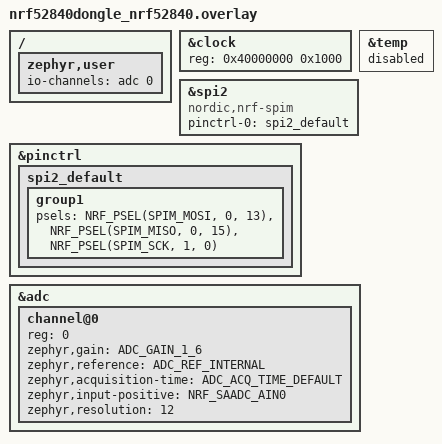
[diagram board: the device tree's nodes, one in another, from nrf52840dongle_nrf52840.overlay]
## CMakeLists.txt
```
cmake_minimum_required(VERSION 3.20.0)
find_package(Zephyr REQUIRED HINTS $ENV{ZEPHYR_BASE})

project(test)

target_sources(app PRIVATE src/main.c)
target_sources(app PRIVATE src/icm42688.c)
```

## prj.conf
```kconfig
CONFIG_SPI=y
CONFIG_GPIO=y
CONFIG_ADC=y
```

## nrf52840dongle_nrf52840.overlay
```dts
// To get started, press Ctrl+Space to bring up the completion menu and view the available nodes.

// You can also use the buttons in the sidebar to perform actions on nodes.
// Actions currently available include:

// * Enabling / disabling the node
// * Adding the bus to a bus
// * Removing the node
// * Connecting ADC channels

// For more help, browse the DeviceTree documentation at https://docs.zephyrproject.org/latest/guides/dts/index.html
// You can also visit the nRF DeviceTree extension documentation at https://nrfconnect.github.io/vscode-nrf-connect/devicetree/nrfdevicetree.html



&clock {
	reg = <0x40000000 0x1000>;
};
/delete-node/ &{/soc/spi@40004000/icm42688@0/};

&temp {
	status = "disabled";
};

&spi2 {
	status = "okay";
	pinctrl-0 = <&spi2_default>;
	pinctrl-names = "default";
	compatible = "nordic,nrf-spim";
};

&pinctrl {
	spi2_default: spi2_default {
		group1 {
			psels = <NRF_PSEL(SPIM_MOSI, 0, 13)>,
					<NRF_PSEL(SPIM_MISO, 0, 15)>,
					<NRF_PSEL(SPIM_SCK, 1, 0)>;
		};
	};
};

&adc {
	#address-cells = <1>;
	#size-cells = <0>;
	status = "okay";
	channel@0 {
		reg = <0>;
		zephyr,gain = "ADC_GAIN_1_6";
		zephyr,reference = "ADC_REF_INTERNAL";
		zephyr,acquisition-time = <ADC_ACQ_TIME_DEFAULT>;
		zephyr,input-positive = <NRF_SAADC_AIN0>;
		zephyr,resolution = <12>;
	};
};

/ {
	zephyr,user {
		io-channels = <&adc 0>;
	};
};
```

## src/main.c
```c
#include <zephyr/kernel.h>
#include <zephyr/drivers/gpio.h>



#define MY_GPIO0 DT_NODELABEL(gpio0)
#define LED_PIN 6

const struct device *gpio0_dev = DEVICE_DT_GET(MY_GPIO0);

int main(void)
{

  gpio_pin_configure(gpio0_dev, LED_PIN, GPIO_OUTPUT);
  
  max30102_init(&max30102, &hi2c1);
  max30102_reset(&max30102);
  max30102_clear_fifo(&max30102);
  max30102_set_fifo_config(&max30102, max30102_smp_ave_8, 1, 7);
  
  // Sensor settings
  max30102_set_led_pulse_width(&max30102, max30102_pw_16_bit);
  max30102_set_adc_resolution(&max30102, max30102_adc_2048);
  max30102_set_sampling_rate(&max30102, max30102_sr_800);
  max30102_set_led_current_1(&max30102, 6.2);
  max30102_set_led_current_2(&max30102, 6.2);

  // Enter SpO2 mode
  max30102_set_mode(&max30102, max30102_spo2);
  max30102_set_a_full(&max30102, 1);
  
  // Initiate 1 temperature measurement
  max30102_set_die_temp_en(&max30102, 1);
  max30102_set_die_temp_rdy(&max30102, 1);
  
  uint8_t en_reg[2] = {0};
  max30102_read(&max30102, 0x00, en_reg, 1);
  
  

  while (1)
  {
    gpio_pin_toggle(gpio0_dev, LED_PIN);

	if (max30102_has_interrupt(&max30102))
    {
      max30102_interrupt_handler(&max30102);
    }
	
    k_msleep(1000);
  }
}
```

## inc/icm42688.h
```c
#pragma once

#include <stdint.h>
#include "icm42688_registers.h"
#include "icm42688_config.h"
#include <zephyr/drivers/spi.h>




typedef struct icm42688_struct icm42688_struct;

// Interfaces
typedef void      (*icm42688_interface_init)					(icm42688_struct*);
typedef int       (*icm42688_interface_begin)			    	(icm42688_struct*);	
typedef int       (*icm42688_interface_spi_init)		        (icm42688_struct*);
typedef int       (*icm42688_interface_spi_begin)		        (icm42688_struct*);	
typedef float     (*icm42688_interface_getTemperature)	    	(icm42688_struct*);
typedef float     (*icm42688_interface_getAccelDataX)	    	(icm42688_struct*);	
typedef float     (*icm42688_interface_getAccelDataY)	    	(icm42688_struct*);	
typedef float     (*icm42688_interface_getAccelDataZ)		    (icm42688_struct*);	
typedef float     (*icm42688_interface_getGyrolDataX)		    (icm42688_struct*);	
typedef float     (*icm42688_interface_getGyroDataY)		    (icm42688_struct*);	
typedef float     (*icm42688_interface_getGyroDataZ)		    (icm42688_struct*);	
typedef void      (*icm42688_interface_tapDetectionInit)		(icm42688_struct*,uint8_t);
typedef void      (*icm42688_interface_getTapInformation)		(icm42688_struct*);
typedef uint8_t   (*icm42688_interface_numberOfTap)	            (icm42688_struct*);
typedef uint8_t   (*icm42688_interface_axisOfTap)	            (icm42688_struct*);
typedef void      (*icm42688_interface_wakeOnMotionInit)		(icm42688_struct*);
typedef void      (*icm42688_interface_setWOMTh)		        (icm42688_struct*,uint8_t,uint8_t);
typedef void      (*icm42688_interface_setWOMInterrupt)		(icm42688_struct*,uint8_t);
typedef void      (*icm42688_interface_enableSMDInterrupt)		(icm42688_struct*,uint8_t);
typedef uint8_t   (*icm42688_interface_readInterruptStatus)	    (icm42688_struct*,uint8_t);
typedef bool      (*icm42688_interface_setODRAndFSR)	        (icm42688_struct*,uint8_t,uint8_t,uint8_t);
typedef void      (*icm42688_interface_startFIFOMode)	        (icm42688_struct*);
typedef void      (*icm42688_interface_stopFIFOMode)	        (icm42688_struct*);
typedef void      (*icm42688_interface_getFIFOData)	            (icm42688_struct*);
typedef void      (*icm42688_interface_setINTMode)	            (icm42688_struct*,uint8_t,uint8_t,uint8_t,uint8_t);
typedef void      (*icm42688_interface_startGyroMeasure)		(icm42688_struct*,uint8_t);
typedef void      (*icm42688_interface_startAccelMeasure)		(icm42688_struct*,uint8_t);
typedef void      (*icm42688_interface_startTempMeasure)	    (icm42688_struct*);

/// @brief Protected
typedef void      (*icm42688_interface_writeReg)				(uint8_t,void*,size_t);
typedef uint8_t    (*icm42688_interface_readReg)				(icm42688_struct*,uint8_t, void*,uint8_t);
typedef void      (*icm42688_interface_setFIFODataMode)	(icm42688_struct*);

/// @brief Private 
typedef void      (*icm42688_interface_setGyroNotchFilterFHz)	(icm42688_struct*,double,uint8_t);
typedef void      (*icm42688_interface_setGyroNFbandwidth)		(icm42688_struct*,uint8_t);
typedef void      (*icm42688_interface_setGyroNotchFilter)		(icm42688_struct*,bool);
typedef void      (*icm42688_interface_setAAFBandwidth)		    (icm42688_struct*,uint8_t,uint8_t);
typedef void      (*icm42688_interface_setAAF)		            (icm42688_struct*,uint8_t,bool);
typedef void      (*icm42688_interface_setUIFilter)		        (icm42688_struct*,uint8_t,uint8_t,uint8_t);

struct icm42688_struct{

  uint8_t _r;
  uint8_t _g;
  uint8_t _b;
  uint8_t _mode;
  uint8_t _tapNum ;
  uint8_t _tapAxis;
  uint8_t _tapDir ;
  float _gyroRange;
  float _accelRange;
  bool FIFOMode;
  int16_t _accelX;
  int16_t _accelY;
  int16_t _accelZ;
  int16_t _gyroX;
  int16_t _gyroZ;
  int16_t _gyroY;
  int8_t _temp;
  int8_t _INTPin;

  sAccelConfig0_t accelConfig0;
  sPWRMgmt0_t PWRMgmt0;
  sINTFConfig1_t INTFConfig1;
  sAccelConfig1_t accelConfig1;
  sGyroAccelConfig0_t gyroAccelConfig0;
  sAPEXConfig7_t APEXConfig7;
  sAPEXConfig8_t APEXConfig8;
  sSMDConfig_t SMDConfig;
  sGyroConfig1_t  gyroConfig1;
  sFIFOConfig1_t FIFOConfig1;
  sINTConfig_t INTConfig;
  sGyroConfig0_t gyroConfig0;
  sAPEXConfig0_t APEXConfig0;
  sGyroConfigStatic9_t gyroConfigStatic9;
  sGyroConfigStatic2_t gyroConfigStatic2;
  sGyroConfigStatic5_t gyroConfigStatic5;
  sAccelConfigStatic2_t accelConfigStatic2;
  sAccelConfigStatic4_t accelConfigStatic4;
  sINTSource_t  INTSource;

  icm42688_interface_begin	                begin;  
  icm42688_interface_spi_init		            spi_init;  
  icm42688_interface_spi_begin		          spi_begin;  
  icm42688_interface_getTemperature	        getTemperature;  
  icm42688_interface_getAccelDataX	        getAccelDataX;  
  icm42688_interface_getAccelDataY	        getAccelDataY;  
  icm42688_interface_getAccelDataZ		      getAccelDataZ;  
  icm42688_interface_getGyrolDataX		      getGyroDataX;  
  icm42688_interface_getGyroDataY		        getGyroDataY;  
  icm42688_interface_getGyroDataZ		        getGyroDataZ;  
  icm42688_interface_tapDetectionInit	      tapDetectionInit;  
  icm42688_interface_getTapInformation	    getTapInformation;  
  icm42688_interface_numberOfTap	          numberOfTap;  
  icm42688_interface_axisOfTap	            axisOfTap;  
  icm42688_interface_wakeOnMotionInit	      wakeOnMotionInit;  
  icm42688_interface_setWOMTh		            setWOMTh;  
  icm42688_interface_setWOMInterrupt        setWOMInterrupt;  
  icm42688_interface_enableSMDInterrupt	    enableSMDInterrupt;  
  icm42688_interface_readInterruptStatus	  readInterruptStatus;  
  icm42688_interface_setODRAndFSR	          setODRAndFSR;  
  icm42688_interface_startFIFOMode	        startFIFOMode;	    
  icm42688_interface_stopFIFOMode	          stopFIFOMode;	   
  icm42688_interface_getFIFOData	          getFIFOData;	         
  icm42688_interface_setINTMode	            setINTMode;	         
  icm42688_interface_startGyroMeasure	      startGyroMeasure;  
  icm42688_interface_startAccelMeasure	    startAccelMeasure;  
  icm42688_interface_startTempMeasure	      startTempMeasure;  
                                                                    
                                                                    
  icm42688_interface_writeReg			          writeReg;			 
  icm42688_interface_readReg				        readReg;		
  icm42688_interface_setFIFODataMode	      setFIFODataMode;	    
                                                                    
                                                                    
  icm42688_interface_setGyroNotchFilterFHz  setGyroNotchFilterFHz; 
  icm42688_interface_setGyroNFbandwidth	    setGyroNFbandwidth;	 
  icm42688_interface_setGyroNotchFilter	    setGyroNotchFilter;	 
  icm42688_interface_setAAFBandwidth		    setAAFBandwidth;		 
  icm42688_interface_setAAF		              setAAF;		         
  icm42688_interface_setUIFilter	          setUIFilter;	         	    


};

void icm42688();
  /**
   * @fn begin
   * @brief Init function
   * @return Init result
   * @retval ERR_OK         Init succeed
   * @retval ERR_DATA_BUS   Bus data read error
   * @retval ERR_IC_VERSION The read Sensor ID is wrong
   */
int icm42688_begin(icm42688_struct *s);

int icm42688_spi_init(icm42688_struct*);

int icm42688_spi_begin(icm42688_struct *s);


void icm42688_writeReg(uint8_t reg, void* pBuf, size_t size) ;

uint8_t icm42688_readReg(icm42688_struct *s,uint8_t reg, void* pBuf, uint8_t size);



float icm42688_getTemperature(icm42688_struct *s);

  /**
   * @fn getAccelDataX
   * @brief Get X-axis accelerometer value
   * @return X-axis accelerometer value, unit: mg
   */
float icm42688_getAccelDataX(icm42688_struct *s);

  /**
   * @fn getAccelDataY
   * @brief Get Y-axis accelerometer value
   * @return Y-axis accelerometer value, unit: mg
   */
float icm42688_getAccelDataY(icm42688_struct *s);

  /**
   * @fn getAccelDataZ
   * @brief Get Z-axis accelerometer value
   * @return Z-axis accelerometer value, unit: mg
   */
float icm42688_getAccelDataZ(icm42688_struct *s);

  /**
   * @fn getGyroDataX
   * @brief Get X-axis gyroscope value
   * @return X-axis gyroscope value, unit: dps
   */
float icm42688_getGyroDataX(icm42688_struct *s);

  /**
   * @fn getGyroDataY
   * @brief Get Y-axis gyroscope value
   * @return Y-axis gyroscope value, unit: dps
   */
float icm42688_getGyroDataY(icm42688_struct *s);

  /**
   * @fn getGyroDataZ
   * @brief Get Z-axis gyroscope value
   * @return Z-axis gyroscope value, unit: dps
   */
float icm42688_getGyroDataZ(icm42688_struct *s);

  /**
   * @fn tapDetectionInit
   * @brief Tap detection init
   * @param accelMode Accelerometer operating mode
   * @n      0 for operating in low-power mode
   * @n      1 for operating in low-noise mode
   */
void icm42688_tapDetectionInit(icm42688_struct *s,uint8_t accelMode);

  /**
   * @fn getTapInformation
   * @brief Get tap information
   */
void icm42688_getTapInformation(icm42688_struct *s);

  /**
   * @fn numberOfTap
   * @brief Get the number of tap: single-tap or double tap
   * @return The number of tap
   * @retval TAP_SINGLE   Single-tap
   * @retval TAP_DOUBLE   Double tap
   */
uint8_t icm42688_numberOfTap(icm42688_struct *s);

  /**
   * @fn axisOfTap
   * @brief Get the axis on which the tap occurred: X-axis, Y-axis, or Z-axis
   * @return Tap axis
   * @retval X_AXIS   X-axis
   * @retval Y_AXIS   Y-axis
   * @retval Z_AXIS   Z-axis
   */
uint8_t icm42688_axisOfTap(icm42688_struct *s);

  /**
   * @fn wakeOnMotionInit
   * @brief Wake on motion init
   */
void icm42688_wakeOnMotionInit(icm42688_struct *s);

  /**
   * @fn setWOMTh
   * @brief Set wake on motion interrupt threshold of axis accelerometer
   * @param axis  x/y/z轴
   * @n       X_AXIS_WOM
   * @n       Y_AXIS_WOM
   * @n       Z_AXIS_WOM
   * @n       ALL
   * @param threshold  Range(0-255) [WoM thresholds are expressed in fixed “mg” independent of the selected Range [0g : 1g]; Resolution 1g/256=~3.9mg]
   */
void icm42688_setWOMTh(icm42688_struct *s,uint8_t axis,uint8_t threshold);

  /**
   * @fn setWOMInterrupt
   * @brief Enable wake on motion interrupt
   * @param axis  X-axis, Y-axis, or Z-axis
   * @n       X_AXIS_WOM
   * @n       Y_AXIS_WOM
   * @n       Z_AXIS_WOM
   */
void icm42688_setWOMInterrupt(icm42688_struct *s,uint8_t axis);

  /**
   * @fn enableSMDInterrupt
   * @brief Set important motion detection mode and enable SMD interrupt
   * @param mode  
   * @n      0: disable SMD
   * @n      2 : SMD short (1 sec wait) An SMD event is detected when two WOM are detected 1 sec apart
   * @n      3 : SMD long (3 sec wait) An SMD event is detected when two WOM are detected 3 sec apart
   */
void icm42688_enableSMDInterrupt(icm42688_struct *s,uint8_t mode);

  /**
   * @fn readInterruptStatus
   * @brief Read interrupt information and clear interrupt
   * @param reg Interrupt information register
   * @n      ICM42688_INT_STATUS2    Obtain interrupt information of SMD_INT, WOM_X_INT, WOM_Y_INT, WOM_Z_INT and clear them
   * @n      ICM42688_INT_STATUS3    Obtain interrupt information of STEP_DET_INT, STEP_CNT_OVF_INT, TILT_DET_INT, WAKE_INT, TAP_DET_INT and clear them
   * @return Interrupt information, return 0 when no interrupt.
   */
uint8_t icm42688_readInterruptStatus(icm42688_struct *s,uint8_t reg);

  /**
   * @fn setODRAndFSR
   * @brief Set ODR and Full-scale range of gyroscope or accelerometer.
   * @param who  GYRO/ACCEL/ALL
   * @n       GYRO: indicate only set gyroscope
   * @n       ACCEL: indicate only set accelerometer
   * @param ODR Output data rate
   * @n       ODR_32KHZ         Support: Gyro/Accel(LN mode)
   * @n       ODR_16KHZ         Support: Gyro/Accel(LN mode)
   * @n       ODR_8KHZ          Support: Gyro/Accel(LN mode)
   * @n       ODR_4KHZ          Support: Gyro/Accel(LN mode)
   * @n       ODR_2KHZ          Support: Gyro/Accel(LN mode)
   * @n       ODR_1KHZ          Support: Gyro/Accel(LN mode)
   * @n       ODR_200HZ         Support: Gyro/Accel(LP or LN mode)
   * @n       ODR_100HZ         Support: Gyro/Accel(LP or LN mode)
   * @n       ODR_50HZ          Support: Gyro/Accel(LP or LN mode)
   * @n       ODR_25KHZ         Support: Gyro/Accel(LP or LN mode)
   * @n       ODR_12_5KHZ       Support: Gyro/Accel(LP or LN mode)
   * @n       ODR_6_25KHZ       Support: Accel(LP mode)
   * @n       ODR_3_125HZ       Support: Accel(LP mode)
   * @n       ODR_1_5625HZ      Support: Accel(LP mode)
   * @n       ODR_500HZ         Support: Accel(LP or LN mode)
   * @param FSR Full-scale range
   * @n       FSR_0      Gyro:±2000dps   /   Accel: ±16g
   * @n       FSR_1      Gyro:±1000dps   /   Accel: ±8g
   * @n       FSR_2      Gyro:±500dps    /   Accel: ±4g
   * @n       FSR_3      Gyro:±250dps    /   Accel: ±2g
   * @n       FSR_4      Gyro:±125dps    /   Accel: not optional
   * @n       FSR_5      Gyro:±62.5dps   /   Accel: not optional
   * @n       FSR_6      Gyro:±31.25dps  /   Accel: not optional
   * @n       FSR_7      Gyro:±15.625dps /   Accel: not optional
   * @return Set result
   * @retval true   indicate the setting succeeds
   * @retval flase  indicate selected parameter is wrong
   */
bool icm42688_setODRAndFSR(icm42688_struct *s,uint8_t who,uint8_t ODR,uint8_t FSR);

  /**
   * @fn startFIFOMode
   * @brief Enable FIFO
   */
void icm42688_startFIFOMode(icm42688_struct *s);

  /**
   * @fn sotpFIFOMode
   * @brief Disable FIFO
   */
void icm42688_stopFIFOMode(icm42688_struct *s);

  /**
   * @fn getFIFOData
   * @brief Read FIFO data, read temperature, gyroscope and accelerometer data and save them for parse.
   */
void icm42688_getFIFOData(icm42688_struct *s);

  /**
   * @fn setINTMode
   * @brief Set interrupt mode
   * @param INTPin  Interrupt pin 
   * @n       1  Use INT1 interrupt pin
   * @n       2  Use INT2 interrupt pin
   * @param INTmode Set interrupt mode
   * @n       1  Interrupt lock mode (polarity remains unchanged when interrupt triggered, and restore after clearing interrupt)
   * @n       0  Pulse mode
   * @param INTPolarity Level polarity output by interrupt
   * @n       0  Interrupt pin polarity is LOW when producing interrupt
   * @n       1  Interrupt pin polarity is HIGH when producing interrupt
   * @param INTDriveCircuit  
   * @n       0  Open drain
   * @n       1  Push pull
   */
void icm42688_setINTMode(icm42688_struct *s,uint8_t INTPin,uint8_t INTmode,uint8_t INTPolarity,uint8_t INTDriveCircuit);

  /**
   * @fn startGyroMeasure
   * @brief Start gyroscope
   * @param mode Set gyroscope working mode
   * @n       STANDBY_MODE_ONLY_GYRO 1  Set stanby mode, only support gyroscope
   * @n       LN_MODE  3                Set low-noise mode
   */
void icm42688_startGyroMeasure(icm42688_struct *s,uint8_t mode);

  /**
   * @fn startAccelMeasure
   * @brief Start accelerometer
   * @param mode Set accelerometer working mode
   * @n       LP_MODE_ONLY_ACCEL  2     Set low-power mode, only support accelerometer
   * @n       LN_MODE  3                Set low-noise mode
   */
void icm42688_startAccelMeasure(icm42688_struct *s,uint8_t mode);

  /**
   * @fn startTempMeasure
   * @brief Start thermometer
   */
void icm42688_startTempMeasure(icm42688_struct *s);


  /**
   * @fn setFIFODataMode
   * @brief Set FIFO data packet format
   */
void icm42688_setFIFODataMode(icm42688_struct *s);
```

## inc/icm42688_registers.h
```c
#define DFRobot_ICM42688_I2C_L_ADDR 0x68 
#define DFRobot_ICM42688_I2C_H_ADDR 0x69
#define DFRobot_ICM42688_ID  0x47 

#define ICM42688_DEVICE_CONFIG          0x11
#define ICM42688_DRIVE_CONFIG           0x13

#define ICM42688_SIGNAL_PATH_RESET      0x4B

#define ICM42688_PWR_MGMT0              0x4E

#define ICM42688_INT_CONFIG             0x14
#define ICM42688_INT_STATUS             0x2D
#define ICM42688_INT_STATUS2            0x37
#define ICM42688_INT_STATUS3            0x38
#define ICM42688_INT_CONFIG0            0x63
#define ICM42688_INT_CONFIG1            0x64
#define ICM42688_INT_SOURCE0            0x65
#define ICM42688_INT_SOURCE1            0x66
#define ICM42688_INT_SOURCE3            0x68
#define ICM42688_INT_SOURCE4            0x69
#define ICM42688_INT_SOURCE6            0x4D
#define ICM42688_INT_SOURCE7            0x4E
#define ICM42688_INT_SOURCE8            0x4F
#define ICM42688_INT_SOURCE9            0x50
#define ICM42688_INT_SOURCE10           0x51

#define ICM42688_TEMP_DATA1             0x1D
#define ICM42688_TEMP_DATA0             0x1E
#define ICM42688_ACCEL_DATA_X1          0x1F
#define ICM42688_ACCEL_DATA_X0          0x20
#define ICM42688_ACCEL_DATA_Y1          0x21
#define ICM42688_ACCEL_DATA_Y0          0x22
#define ICM42688_ACCEL_DATA_Z1          0x23
#define ICM42688_ACCEL_DATA_Z0          0x24
#define ICM42688_GYRO_DATA_X1           0x25
#define ICM42688_GYRO_DATA_X0           0x26
#define ICM42688_GYRO_DATA_Y1           0x27
#define ICM42688_GYRO_DATA_Y0           0x28
#define ICM42688_GYRO_DATA_Z1           0x29
#define ICM42688_GYRO_DATA_Z0           0x30

#define ICM42688_TMST_FSYNCH            0x43
#define ICM42688_TMST_FSYNCL            0x44

#define ICM42688_GYRO_CONFIG_STATIC2    0x0B
#define ICM42688_GYRO_CONFIG_STATIC3    0x0C
#define ICM42688_GYRO_CONFIG_STATIC4    0x0D
#define ICM42688_GYRO_CONFIG_STATIC5    0x0E
#define ICM42688_GYRO_CONFIG_STATIC6    0x0F
#define ICM42688_GYRO_CONFIG_STATIC7    0x10
#define ICM42688_GYRO_CONFIG_STATIC8    0x11
#define ICM42688_GYRO_CONFIG_STATIC9    0x12
#define ICM42688_GYRO_CONFIG_STATIC10   0x13


    
#define ICM42688_GYRO_CONFIG0           0x4F
#define ICM42688_ACCEL_CONFIG0          0x50
#define ICM42688_GYRO_CONFIG1           0x51
#define ICM42688_GYRO_ACCEL_CONFIG0     0x52
#define ICM42688_ACCEL_CONFIG1          0x53
    
#define ICM42688_TMST_CONFIG            0x54
    

#define ICM42688_SMD_CONFIG             0x57

#define ICM42688_FIFO_CONFIG            0x16
#define ICM42688_FIFO_COUNTH            0x2E
#define ICM42688_FIFO_COUNTL            0x2F
#define ICM42688_FIFO_DATA              0x30
#define ICM42688_FIFO_CONFIG1           0x5F
#define ICM42688_FIFO_CONFIG2           0x60
#define ICM42688_FIFO_CONFIG3           0x61
#define ICM42688_FIFO_LOST_PKT0         0x6C
#define ICM42688_FIFO_LOST_PKT1         0x6D

#define ICM42688_FSYNC_CONFIG           0x62
    

    

#define ICM42688_SELF_TEST_CONFIG       0x70
#define ICM42688_WHO_AM_I               0x75
#define ICM42688_REG_BANK_SEL           0x76   
#define ICM42688_SENSOR_CONFIG0         0x03



#define ICM42688_XG_ST_DATA             0x5F
#define ICM42688_YG_ST_DATA             0x60
#define ICM42688_ZG_ST_DATA             0x61

#define ICM42688_TMSTVAL0               0x62
#define ICM42688_TMSTVAL1               0x63
#define ICM42688_TMSTVAL2               0x64

#define ICM42688_INTF_CONFIG0           0x4C
#define ICM42688_INTF_CONFIG1           0x4D
#define ICM42688_INTF_CONFIG4           0x7A
#define ICM42688_INTF_CONFIG5           0x7B
#define ICM42688_INTF_CONFIG6           0x7C

#define ICM42688_ACCEL_CONFIG_STATIC2   0x03
#define ICM42688_ACCEL_CONFIG_STATIC3   0x04
#define ICM42688_ACCEL_CONFIG_STATIC4   0x05

#define ICM42688_XA_ST_DATA             0x3B
#define ICM42688_YA_ST_DATA             0x3C
#define ICM42688_ZA_ST_DATA             0x3D

#define ICM42688_APEX_DATA0             0x31
#define ICM42688_APEX_DATA1             0x32
#define ICM42688_APEX_DATA2             0x33
#define ICM42688_APEX_DATA3             0x34
#define ICM42688_APEX_DATA4             0x35
#define ICM42688_APEX_DATA5             0x36
#define ICM42688_APEX_CONFIG0           0x56
#define ICM42688_APEX_CONFIG1           0x40 
#define ICM42688_APEX_CONFIG2           0x41
#define ICM42688_APEX_CONFIG3           0x42
#define ICM42688_APEX_CONFIG4           0x43
#define ICM42688_APEX_CONFIG5           0x44
#define ICM42688_APEX_CONFIG6           0x45
#define ICM42688_APEX_CONFIG7           0x46
#define ICM42688_APEX_CONFIG8           0x47
#define ICM42688_APEX_CONFIG9           0x48

#define ICM42688_ACCEL_WOM_X_THR        0x4A
#define ICM42688_ACCEL_WOM_Y_THR        0x4B
#define ICM42688_ACCEL_WOM_Z_THR        0x4C

#define ICM42688_OFFSET_USER0           0x77
#define ICM42688_OFFSET_USER1           0x78
#define ICM42688_OFFSET_USER2           0x79
#define ICM42688_OFFSET_USER3           0x7A
#define ICM42688_OFFSET_USER4           0x7B
#define ICM42688_OFFSET_USER5           0x7C
#define ICM42688_OFFSET_USER6           0x7D
#define ICM42688_OFFSET_USER7           0x7E
#define ICM42688_OFFSET_USER8           0x7F

#define ICM42688_STEP_DET_INT           1<<5
#define ICM42688_STEP_CNT_OVF_INT       1<<4
#define ICM42688_TILT_DET_INT           1<<3
#define ICM42688_WAKE_INT               1<<2
#define ICM42688_SLEEP_INT              1<<1
#define ICM42688_TAP_DET_INT            1

#define ICM42688_SMD_INT                1<<3
#define ICM42688_WOM_Z_INT              1<<2
#define ICM42688_WOM_Y_INT              1<<1
#define ICM42688_WOM_X_INT              1

#define ICM42688_STATUS_WALK 1
#define ICM42688_STATUS_RUN 2

//////////////////////////////////////////////////////////////////////////////////////////////////////


  #define ERR_OK             0      ///< No error
  #define ERR_DATA_BUS      -1      ///< Data bus error
  #define ERR_IC_VERSION    -2      ///< The chip version not match
  
  #define GYRO     0
  #define ACCEL    1
  #define ALL      5



  #define TMST_DEFAULT_CONFIG_START  0x23
  #define TMST_VALUE_DIS             0<<4
  #define TMST_VALUE_EN              1<<4
  #define TMST_RES_EN_DIS            0<<3 
  #define TMST_RES_EN                1<<3
  #define TMST_FSYNC_EN              1<<1
  #define TMST_FSYNC_DIS             0<<1
  #define TMST_DELTA_EN              0<<2
  #define TMST_DELTA_DIS             1<<2
  #define TMST_EN                    1
  #define TMST_DIS                   0

  #define X_AXIS   0
  #define Y_AXIS   2
  #define Z_AXIS   4

  #define X_AXIS_WOM   1
  #define Y_AXIS_WOM   2
  #define Z_AXIS_WOM   4

  #define ODR_32KHZ         1
  #define ODR_16KHZ         2
  #define ODR_8KHZ          3
  #define ODR_4KHZ          4
  #define ODR_2KHZ          5
  #define ODR_1KHZ          6
  #define ODR_200HZ         7
  #define ODR_100HZ         8
  #define ODR_50HZ          9
  #define ODR_25KHZ         10
  #define ODR_12_5KHZ       11
  #define ODR_6_25KHZ       12
  #define ODR_3_125HZ       13
  #define ODR_1_5625HZ      14
  #define ODR_500HZ         15

  #define FSR_0             0
  #define FSR_1             1
  #define FSR_2             2
  #define FSR_3             3
  #define FSR_4             4
  #define FSR_5             5
  #define FSR_6             6
  #define FSR_7             7

  #define LP_MODE_ONLY_ACCEL  2
  #define LN_MODE  3
  #define STANDBY_MODE_ONLY_GYRO 1 
  #define OFF_MODE   0

  #define TAP_SINGLE 8
  #define TAP_DOUBLE 16
```

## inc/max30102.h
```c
#pragma once


#include "max30102_defines.h"


#include "main.h"
#include <stdint.h>
#include <string.h>
#include <stdlib.h>
#include <string.h>


typedef enum max30102_mode_t
{
    max30102_heart_rate = 0x02,
    max30102_spo2 = 0x03,
    max30102_multi_led = 0x07
} max30102_mode_t;

typedef enum max30102_smp_ave_t
{
    max30102_smp_ave_1,
    max30102_smp_ave_2,
    max30102_smp_ave_4,
    max30102_smp_ave_8,
    max30102_smp_ave_16,
    max30102_smp_ave_32,
} max30102_smp_ave_t;

typedef enum max30102_sr_t
{
    max30102_sr_50,
    max30102_sr_100,
    max30102_sr_200,
    max30102_sr_400,
    max30102_sr_800,
    max30102_sr_1000,
    max30102_sr_1600,
    max30102_sr_3200
} max30102_sr_t;

typedef enum max30102_led_pw_t
{
    max30102_pw_15_bit,
    max30102_pw_16_bit,
    max30102_pw_17_bit,
    max30102_pw_18_bit
} max30102_led_pw_t;

typedef enum max30102_adc_t
{
    max30102_adc_2048,
    max30102_adc_4096,
    max30102_adc_8192,
    max30102_adc_16384
} max30102_adc_t;

typedef enum max30102_multi_led_ctrl_t
{
    max30102_led_off,
    max30102_led_red,
    max30102_led_ir
} max30102_multi_led_ctrl_t;

typedef struct max30102_t
{
    I2C_HandleTypeDef *_ui2c;
    uint32_t _ir_samples[32];
    uint32_t _red_samples[32];
    uint8_t _interrupt_flag;
} max30102_t;

void max30102_plot(uint32_t ir_sample, uint32_t red_sample);

void max30102_init(max30102_t *obj, I2C_HandleTypeDef *hi2c);
void max30102_write(max30102_t *obj, uint8_t reg, uint8_t *buf, uint16_t buflen);
void max30102_read(max30102_t *obj, uint8_t reg, uint8_t *buf, uint16_t buflen);

void max30102_reset(max30102_t *obj);

void max30102_set_a_full(max30102_t *obj, uint8_t enable);
void max30102_set_ppg_rdy(max30102_t *obj, uint8_t enable);
void max30102_set_alc_ovf(max30102_t *obj, uint8_t enable);
void max30102_set_die_temp_rdy(max30102_t *obj, uint8_t enable);
void max30102_set_die_temp_en(max30102_t *obj, uint8_t enable);

void max30102_on_interrupt(max30102_t *obj);
uint8_t max30102_has_interrupt(max30102_t *obj);
void max30102_interrupt_handler(max30102_t *obj);

void max30102_shutdown(max30102_t *obj, uint8_t shdn);

void max30102_set_mode(max30102_t *obj, max30102_mode_t mode);
void max30102_set_sampling_rate(max30102_t *obj, max30102_sr_t sr);

void max30102_set_led_pulse_width(max30102_t *obj, max30102_led_pw_t pw);
void max30102_set_adc_resolution(max30102_t *obj, max30102_adc_t adc);

void max30102_set_led_current_1(max30102_t *obj, float ma);
void max30102_set_led_current_2(max30102_t *obj, float ma);
void max30102_set_multi_led_slot_1_2(max30102_t *obj, max30102_multi_led_ctrl_t slot1, max30102_multi_led_ctrl_t slot2);
void max30102_set_multi_led_slot_3_4(max30102_t *obj, max30102_multi_led_ctrl_t slot3, max30102_multi_led_ctrl_t slot4);

void max30102_set_fifo_config(max30102_t *obj, max30102_smp_ave_t smp_ave, uint8_t roll_over_en, uint8_t fifo_a_full);
void max30102_clear_fifo(max30102_t *obj);
void max30102_read_fifo(max30102_t *obj);

void max30102_read_temp(max30102_t *obj, int8_t *temp_int, uint8_t *temp_frac);

#endif
```

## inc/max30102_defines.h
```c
#pragma once

#define MAX30102_I2C_ADDR 0x57
#define MAX30102_I2C_TIMEOUT 1000

#define MAX30102_BYTES_PER_SAMPLE 6
#define MAX30102_SAMPLE_LEN_MAX 32

#define MAX30102_INTERRUPT_STATUS_1 0x00
#define MAX30102_INTERRUPT_STATUS_2 0x01
#define MAX30102_INTERRUPT_ENABLE_1 0x02
#define MAX30102_INTERRUPT_ENABLE_2 0x03
#define MAX30102_INTERRUPT_A_FULL 7
#define MAX30102_INTERRUPT_PPG_RDY 6
#define MAX30102_INTERRUPT_ALC_OVF 5
#define MAX30102_INTERRUPT_DIE_TEMP_RDY 1

#define MAX30102_FIFO_WR_PTR 0x04
#define MAX30102_OVF_COUNTER 0x05
#define MAX30102_FIFO_RD_PTR 0x06

#define MAX30102_FIFO_DATA 0x07

#define MAX30102_FIFO_CONFIG 0x08
#define MAX30102_FIFO_CONFIG_SMP_AVE 5
#define MAX30102_FIFO_CONFIG_ROLL_OVER_EN 4
#define MAX30102_FIFO_CONFIG_FIFO_A_FULL 0

#define MAX30102_MODE_CONFIG 0x09
#define MAX30102_MODE_SHDN 7
#define MAX30102_MODE_RESET 6
#define MAX30102_MODE_MODE 0

#define MAX30102_SPO2_CONFIG 0x0a
#define MAX30102_SPO2_ADC_RGE 5
#define MAX30102_SPO2_SR 2
#define MAX30102_SPO2_LEW_PW 0

#define MAX30102_LED_IR_PA1 0x0c
#define MAX30102_LED_RED_PA2 0x0d

#define MAX30102_MULTI_LED_CTRL_1 0x11
#define MAX30102_MULTI_LED_CTRL_SLOT2 4
#define MAX30102_MULTI_LED_CTRL_SLOT1 0
#define MAX30102_MULTI_LED_CTRL_2 0x12
#define MAX30102_MULTI_LED_CTRL_SLOT4 4
#define MAX30102_MULTI_LED_CTRL_SLOT3 0

#define MAX30102_DIE_TINT 0x1f
#define MAX30102_DIE_TFRAC 0x20
#define MAX30102_DIE_TFRAC_INCREMENT 0.0625f
#define MAX30102_DIE_TEMP_CONFIG 0x21
#define MAX30102_DIE_TEMP_EN 1


// FOR TEST 
#define DEBUG_PRINT
```

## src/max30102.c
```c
#include "max30102.h"

#include <zephyr.h>
#include <device.h>
#include <drivers/i2c.h>
#include <stdio.h>

#ifdef __cplusplus
extern "C"
{
#endif

/**
 * @brief Built-in plotting function. Called during an interrupt to print/plot the current sample.
 * @note Override this in your main.c if you do not use printf() for printing.
 * @param ir_sample
 * @param red_sample
 */
__weak void max30102_plot(uint32_t ir_sample, uint32_t red_sample)
{
    UNUSED(ir_sample);
    UNUSED(red_sample);
}

void max30102_init(struct max30102 *obj, const struct device *i2c_dev)
{
    obj->i2c_dev = i2c_dev;
    obj->_interrupt_flag = 0;
    memset(obj->_ir_samples, 0, MAX30102_SAMPLE_LEN_MAX * sizeof(uint32_t));
    memset(obj->_red_samples, 0, MAX30102_SAMPLE_LEN_MAX * sizeof(uint32_t));
}


void max30102_write(struct max30102_t *obj, uint8_t reg, uint8_t *buf, uint16_t buflen)
{
    uint8_t *payload = (uint8_t *)k_malloc((buflen + 1) * sizeof(uint8_t));
    payload[0] = reg;
    if (buf != NULL && buflen != 0) {
        memcpy(payload + 1, buf, buflen);
    }
    
    int ret = i2c_write(obj->i2c_dev, payload, buflen + 1, MAX30102_I2C_ADDR);
    if (ret) {
        printk("I2C write error: %d\n", ret);
    }
    
    k_free(payload);
}

void max30102_read(struct max30102_t *obj, uint8_t reg, uint8_t *buf, uint16_t buflen)
{
    int ret = i2c_write_read(obj->i2c_dev, MAX30102_I2C_ADDR, &reg, 1, buf, buflen);
    if (ret) {
        printk("I2C read error: %d\n", ret);
    }
}

/**
 * @brief Reset the sensor.
 *
 * @param obj Pointer to max30102_t object instance.
 */
void max30102_reset(max30102_t *obj)
{
    uint8_t val = 0x40;
    max30102_write(obj, MAX30102_MODE_CONFIG, &val, 1);
}

/**
 * @brief Enable A_FULL interrupt.
 *
 * @param obj Pointer to max30102_t object instance.
 * @param enable Enable (1) or disable (0).
 */
void max30102_set_a_full(max30102_t *obj, uint8_t enable)
{
    uint8_t reg = 0;
    max30102_read(obj, MAX30102_INTERRUPT_ENABLE_1, &reg, 1);
    reg &= ~(0x01 << MAX30102_INTERRUPT_A_FULL);
    reg |= ((enable & 0x01) << MAX30102_INTERRUPT_A_FULL);
    max30102_write(obj, MAX30102_INTERRUPT_ENABLE_1, &reg, 1);
}

/**
 * @brief Enable PPG_RDY interrupt.
 *
 * @param obj Pointer to max30102_t object instance.
 * @param enable Enable (1) or disable (0).
 */
void max30102_set_ppg_rdy(max30102_t *obj, uint8_t enable)
{
    uint8_t reg = 0;
    max30102_read(obj, MAX30102_INTERRUPT_ENABLE_1, &reg, 1);
    reg &= ~(0x01 << MAX30102_INTERRUPT_PPG_RDY);
    reg |= ((enable & 0x01) << MAX30102_INTERRUPT_PPG_RDY);
    max30102_write(obj, MAX30102_INTERRUPT_ENABLE_1, &reg, 1);
}

/**
 * @brief Enable ALC_OVF interrupt.
 *
 * @param obj Pointer to max30102_t object instance.
 * @param enable Enable (1) or disable (0).
 */
void max30102_set_alc_ovf(max30102_t *obj, uint8_t enable)
{
    uint8_t reg = 0;
    max30102_read(obj, MAX30102_INTERRUPT_ENABLE_1, &reg, 1);
    reg &= ~(0x01 << MAX30102_INTERRUPT_ALC_OVF);
    reg |= ((enable & 0x01) << MAX30102_INTERRUPT_ALC_OVF);
    max30102_write(obj, MAX30102_INTERRUPT_ENABLE_1, &reg, 1);
}

/**
 * @brief Enable DIE_TEMP_RDY interrupt.
 *
 * @param obj Pointer to max30102_t object instance.
 * @param enable Enable (1) or disable (0).
 */
void max30102_set_die_temp_rdy(max30102_t *obj, uint8_t enable)
{
    uint8_t reg = (enable & 0x01) << MAX30102_INTERRUPT_DIE_TEMP_RDY;
    max30102_write(obj, MAX30102_INTERRUPT_ENABLE_2, &reg, 1);
}

/**
 * @brief Enable temperature measurement.
 *
 * @param obj Pointer to max30102_t object instance.
 * @param enable Enable (1) or disable (0).
 */
void max30102_set_die_temp_en(max30102_t *obj, uint8_t enable)
{
    uint8_t reg = (enable & 0x01) << MAX30102_DIE_TEMP_EN;
    max30102_write(obj, MAX30102_DIE_TEMP_CONFIG, &reg, 1);
}

/**
 * @brief Set interrupt flag on interrupt. To be called in the corresponding external interrupt handler.
 *
 * @param obj Pointer to max30102_t object instance.
 */
void max30102_on_interrupt(max30102_t *obj)
{
    obj->_interrupt_flag = 1;
}

/**
 * @brief Check whether the interrupt flag is active.
 *
 * @param obj Pointer to max30102_t object instance.
 * @return uint8_t Active (1) or inactive (0).
 */
uint8_t max30102_has_interrupt(max30102_t *obj)
{
    return obj->_interrupt_flag;
}

/**
 * @brief Read interrupt status registers (0x00 and 0x01) and perform corresponding tasks.
 *
 * @param obj Pointer to max30102_t object instance.
 */
void max30102_interrupt_handler(max30102_t *obj)
{
    uint8_t reg[2] = {0x00};
    // Interrupt flag in registers 0x00 and 0x01 are cleared on read
    max30102_read(obj, MAX30102_INTERRUPT_STATUS_1, reg, 2);

    if ((reg[0] >> MAX30102_INTERRUPT_A_FULL) & 0x01)
    {
        // FIFO almost full
        max30102_read_fifo(obj);
    }

    if ((reg[0] >> MAX30102_INTERRUPT_PPG_RDY) & 0x01)
    {
        // New FIFO data ready
    }

    if ((reg[0] >> MAX30102_INTERRUPT_ALC_OVF) & 0x01)
    {
        // Ambient light overflow
    }

    if ((reg[1] >> MAX30102_INTERRUPT_DIE_TEMP_RDY) & 0x01)
    {
        // Temperature data ready
        int8_t temp_int;
        uint8_t temp_frac;
        max30102_read_temp(obj, &temp_int, &temp_frac);
        // float temp = temp_int + 0.0625f * temp_frac;
    }

    // Reset interrupt flag
    obj->_interrupt_flag = 0;
}

/**
 * @brief Shutdown the sensor.
 *
 * @param obj Pointer to max30102_t object instance.
 * @param shdn Shutdown bit.
 */
void max30102_shutdown(max30102_t *obj, uint8_t shdn)
{
    uint8_t config;
    max30102_read(obj, MAX30102_MODE_CONFIG, &config, 1);
    config = (config & 0x7f) | (shdn << MAX30102_MODE_SHDN);
    max30102_write(obj, MAX30102_MODE_CONFIG, &config, 1);
}

/**
 * @brief Set measurement mode.
 *
 * @param obj Pointer to max30102_t object instance.
 * @param mode Measurement mode enum (max30102_mode_t).
 */
void max30102_set_mode(max30102_t *obj, max30102_mode_t mode)
{
    uint8_t config;
    max30102_read(obj, MAX30102_MODE_CONFIG, &config, 1);
    config = (config & 0xf8) | mode;
    max30102_write(obj, MAX30102_MODE_CONFIG, &config, 1);
    max30102_clear_fifo(obj);
}

/**
 * @brief Set sampling rate.
 *
 * @param obj Pointer to max30102_t object instance.
 * @param sr Sampling rate enum (max30102_spo2_st_t).
 */
void max30102_set_sampling_rate(max30102_t *obj, max30102_sr_t sr)
{
    uint8_t config;
    max30102_read(obj, MAX30102_SPO2_CONFIG, &config, 1);
    config = (config & 0x63) << MAX30102_SPO2_SR;
    max30102_write(obj, MAX30102_SPO2_CONFIG, &config, 1);
}

/**
 * @brief Set led pulse width.
 *
 * @param obj Pointer to max30102_t object instance.
 * @param pw Pulse width enum (max30102_led_pw_t).
 */
void max30102_set_led_pulse_width(max30102_t *obj, max30102_led_pw_t pw)
{
    uint8_t config;
    max30102_read(obj, MAX30102_SPO2_CONFIG, &config, 1);
    config = (config & 0x7c) | (pw << MAX30102_SPO2_LEW_PW);
    max30102_write(obj, MAX30102_SPO2_CONFIG, &config, 1);
}

/**
 * @brief Set ADC resolution.
 *
 * @param obj Pointer to max30102_t object instance.
 * @param adc ADC resolution enum (max30102_adc_t).
 */
void max30102_set_adc_resolution(max30102_t *obj, max30102_adc_t adc)
{
    uint8_t config;
    max30102_read(obj, MAX30102_SPO2_CONFIG, &config, 1);
    config = (config & 0x1f) | (adc << MAX30102_SPO2_ADC_RGE);
    max30102_write(obj, MAX30102_SPO2_CONFIG, &config, 1);
}

/**
 * @brief Set LED current.
 *
 * @param obj Pointer to max30102_t object instance.
 * @param ma LED current float (0 < ma < 51.0).
 */
void max30102_set_led_current_1(max30102_t *obj, float ma)
{
    uint8_t pa = ma / 0.2;
    max30102_write(obj, MAX30102_LED_IR_PA1, &pa, 1);
}

/**
 * @brief Set LED current.
 *
 * @param obj Pointer to max30102_t object instance.
 * @param ma LED current float (0 < ma < 51.0).
 */
void max30102_set_led_current_2(max30102_t *obj, float ma)
{
    uint8_t pa = ma / 0.2;
    max30102_write(obj, MAX30102_LED_RED_PA2, &pa, 1);
}

/**
 * @brief Set slot mode when in multi-LED mode.
 *
 * @param obj Pointer to max30102_t object instance.
 * @param slot1 Slot 1 mode enum (max30102_multi_led_ctrl_t).
 * @param slot2 Slot 2 mode enum (max30102_multi_led_ctrl_t).
 */
void max30102_set_multi_led_slot_1_2(max30102_t *obj, max30102_multi_led_ctrl_t slot1, max30102_multi_led_ctrl_t slot2)
{
    uint8_t val = 0;
    val |= ((slot1 << MAX30102_MULTI_LED_CTRL_SLOT1) | (slot2 << MAX30102_MULTI_LED_CTRL_SLOT2));
    max30102_write(obj, MAX30102_MULTI_LED_CTRL_1, &val, 1);
}

/**
 * @brief Set slot mode when in multi-LED mode.
 *
 * @param obj Pointer to max30102_t object instance.
 * @param slot1 Slot 1 mode enum (max30102_multi_led_ctrl_t).
 * @param slot2 Slot 2 mode enum (max30102_multi_led_ctrl_t).
 */
void max30102_set_multi_led_slot_3_4(max30102_t *obj, max30102_multi_led_ctrl_t slot3, max30102_multi_led_ctrl_t slot4)
{
    uint8_t val = 0;
    val |= ((slot3 << MAX30102_MULTI_LED_CTRL_SLOT3) | (slot4 << MAX30102_MULTI_LED_CTRL_SLOT4));
    max30102_write(obj, MAX30102_MULTI_LED_CTRL_2, &val, 1);
}

/**
 * @brief
 *
 * @param obj Pointer to max30102_t object instance.
 * @param smp_ave
 * @param roll_over_en Roll over enabled(1) or disabled(0).
 * @param fifo_a_full Number of empty samples when A_FULL interrupt issued (0 < fifo_a_full < 15).
 */
void max30102_set_fifo_config(max30102_t *obj, max30102_smp_ave_t smp_ave, uint8_t roll_over_en, uint8_t fifo_a_full)
{
    uint8_t config = 0x00;
    config |= smp_ave << MAX30102_FIFO_CONFIG_SMP_AVE;
    config |= ((roll_over_en & 0x01) << MAX30102_FIFO_CONFIG_ROLL_OVER_EN);
    config |= ((fifo_a_full & 0x0f) << MAX30102_FIFO_CONFIG_FIFO_A_FULL);
    max30102_write(obj, MAX30102_FIFO_CONFIG, &config, 1);
}

/**
 * @brief Clear all FIFO pointers in the sensor.
 * @param obj Pointer to max30102_t object instance.
 */
void max30102_clear_fifo(max30102_t *obj)
{
    uint8_t val = 0x00;
    max30102_write(obj, MAX30102_FIFO_WR_PTR, &val, 3);
    max30102_write(obj, MAX30102_FIFO_RD_PTR, &val, 3);
    max30102_write(obj, MAX30102_OVF_COUNTER, &val, 3);
}

/**
 * @brief Read FIFO content and store to buffer in max30102_t object instance.
 *
 * @param obj Pointer to max30102_t object instance.
 */
void max30102_read_fifo(max30102_t *obj)
{
    // First transaction: Get the FIFO_WR_PTR
    uint8_t wr_ptr = 0, rd_ptr = 0;
    max30102_read(obj, MAX30102_FIFO_WR_PTR, &wr_ptr, 1);
    max30102_read(obj, MAX30102_FIFO_RD_PTR, &rd_ptr, 1);

    int8_t num_samples;

    num_samples = (int8_t)wr_ptr - (int8_t)rd_ptr;
    if (num_samples < 1)
    {
        num_samples += 32;
    }

    // Second transaction: Read NUM_SAMPLES_TO_READ samples from the FIFO
    for (int8_t i = 0; i < num_samples; i++)
    {
        uint8_t sample[6];
        max30102_read(obj, MAX30102_FIFO_DATA, sample, 6);
        uint32_t ir_sample = ((uint32_t)(sample[0] << 16) | (uint32_t)(sample[1] << 8) | (uint32_t)(sample[2])) & 0x3ffff;
        uint32_t red_sample = ((uint32_t)(sample[3] << 16) | (uint32_t)(sample[4] << 8) | (uint32_t)(sample[5])) & 0x3ffff;
        obj->_ir_samples[i] = ir_sample;
        obj->_red_samples[i] = red_sample;
        max30102_plot(ir_sample, red_sample);
    }
}

/**
 * @brief Read die temperature.
 *
 * @param obj Pointer to max30102_t object instance.
 * @param temp_int Pointer to store the integer part of temperature. Stored in 2's complement format.
 * @param temp_frac Pointer to store the fractional part of temperature. Increments of 0.0625 deg C.
 */

void max30102_read_temp(max30102_t *obj, int8_t *temp_int, uint8_t *temp_frac)
{
    max30102_read(obj, MAX30102_DIE_TINT, (uint8_t *)temp_int, 1);
    max30102_read(obj, MAX30102_DIE_TFRAC, temp_frac, 1);
	
	#ifdef DEBUG_PRINT
	printk("Temp = %d \r\n", temp_int);
	#endif
}

#ifdef __cplusplus
}
#endif
```
